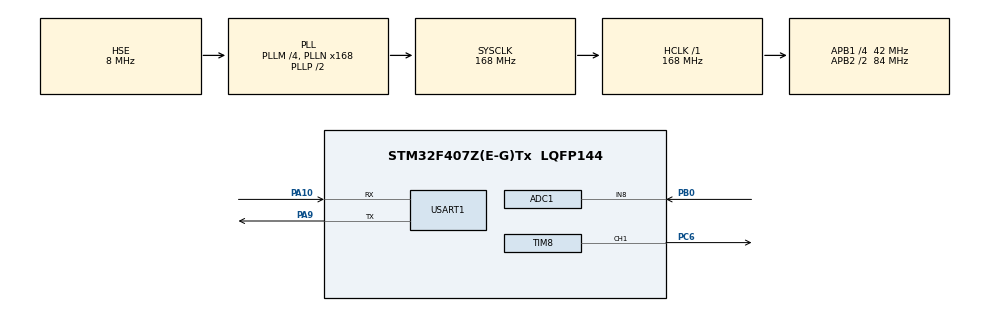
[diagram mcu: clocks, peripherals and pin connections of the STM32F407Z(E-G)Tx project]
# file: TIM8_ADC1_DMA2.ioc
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ADC1.Channel-0\#ChannelRegularConversion=ADC_CHANNEL_8
ADC1.DMAContinuousRequests=ENABLE
ADC1.ExternalTrigConv=ADC_EXTERNALTRIGCONV_T8_CC1
ADC1.NbrOfConversionFlag=1
ADC1.Rank-0\#ChannelRegularConversion=1
ADC1.SamplingTime-0\#ChannelRegularConversion=ADC_SAMPLETIME_15CYCLES
ADC1.master=1
Dma.ADC1.0.Direction=DMA_PERIPH_TO_MEMORY
Dma.ADC1.0.FIFOMode=DMA_FIFOMODE_DISABLE
Dma.ADC1.0.Instance=DMA2_Stream0
Dma.ADC1.0.MemDataAlignment=DMA_MDATAALIGN_HALFWORD
Dma.ADC1.0.MemInc=DMA_MINC_ENABLE
Dma.ADC1.0.Mode=DMA_NORMAL
Dma.ADC1.0.PeriphDataAlignment=DMA_PDATAALIGN_HALFWORD
Dma.ADC1.0.PeriphInc=DMA_PINC_DISABLE
Dma.ADC1.0.Priority=DMA_PRIORITY_MEDIUM
Dma.Request0=ADC1
Mcu.Family=STM32F4
Mcu.Name=STM32F407Z(E-G)Tx
Mcu.Package=LQFP144
NVIC.DMA2_Stream0_IRQn=true\:0\:0\:false\:false\:true\:false\:true\:true
NVIC.PriorityGroup=NVIC_PRIORITYGROUP_4
PA10.Mode=Asynchronous
PA10.Signal=USART1_RX
PA13.Mode=Serial_Wire
PA13.Signal=SYS_JTMS-SWDIO
PA14.Mode=Serial_Wire
PA14.Signal=SYS_JTCK-SWCLK
PA9.Mode=Asynchronous
PA9.Signal=USART1_TX
PB0.Signal=ADCx_IN8
PC14-OSC32_IN.Mode=LSE-External-Oscillator
PC14-OSC32_IN.Signal=RCC_OSC32_IN
PC15-OSC32_OUT.Mode=LSE-External-Oscillator
PC15-OSC32_OUT.Signal=RCC_OSC32_OUT
PC6.Signal=S_TIM8_CH1
PH0-OSC_IN.Mode=HSE-External-Oscillator
PH0-OSC_IN.Signal=RCC_OSC_IN
PH1-OSC_OUT.Mode=HSE-External-Oscillator
PH1-OSC_OUT.Signal=RCC_OSC_OUT
ProjectManager.HeapSize=0x200
ProjectManager.StackSize=0x400
ProjectManager.TargetToolchain=MDK-ARM V5.32
RCC.48MHZClocksFreq_Value=84000000
RCC.AHBFreq_Value=168000000
RCC.APB1CLKDivider=RCC_HCLK_DIV4
RCC.APB1Freq_Value=42000000
RCC.APB1TimFreq_Value=84000000
RCC.APB2CLKDivider=RCC_HCLK_DIV2
RCC.APB2Freq_Value=84000000
RCC.APB2TimFreq_Value=168000000
RCC.CortexFreq_Value=168000000
RCC.HCLKFreq_Value=168000000
RCC.HSE_VALUE=8000000
RCC.HSI_VALUE=16000000
RCC.PLLM=4
RCC.PLLN=168
RCC.PLLSourceVirtual=RCC_PLLSOURCE_HSE
RCC.SYSCLKFreq_VALUE=168000000
RCC.SYSCLKSource=RCC_SYSCLKSOURCE_PLLCLK
RCC.VCOOutputFreq_Value=336000000
SH.ADCx_IN8.0=ADC1_IN8,IN8
SH.S_TIM8_CH1.0=TIM8_CH1,PWM Generation1 CH1
TIM8.Channel-PWM\ Generation1\ CH1=TIM_CHANNEL_1
TIM8.OCPolarity_1=TIM_OCPOLARITY_LOW
TIM8.Period=7999
TIM8.Prescaler=41999
TIM8.Pulse-PWM\ Generation1\ CH1=2999
TIM8.TIM_MasterOutputTrigger=TIM_TRGO_UPDATE
TIM8.TIM_MasterSlaveMode=TIM_MASTERSLAVEMODE_ENABLE
USART1.VirtualMode=VM_ASYNC
VP_TIM8_VS_ClockSourceINT.Mode=Internal
board=custom

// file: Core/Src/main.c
/* USER CODE BEGIN Header */
/**
  ******************************************************************************
  * @file           : main.c
  * @brief          : Main program body
  ******************************************************************************
  * @attention
  *
  * Copyright (c) 2025 STMicroelectronics.
  * All rights reserved.
  *
  * This software is licensed under terms that can be found in the LICENSE file
  * in the root directory of this software component.
  * If no LICENSE file comes with this software, it is provided AS-IS.
  *
  ******************************************************************************
  */
/* USER CODE END Header */
#include "main.h"
#include "adc.h"
#include "dma.h"
#include "tim.h"
#include "usart.h"
#include "gpio.h"
#include "stdio.h"

/* USER CODE BEGIN PD */
#define  ADC_DMA_BUF_SIZE    256         /* ADC DMA采集 BUF大小, 应等于ADC通道数的整数倍 */
#define FRAME_HEADER        0xAA        /* 帧头 */
#define FRAME_TAIL         0xBB        /* 帧尾 */
/* USER CODE END PD */

/* USER CODE BEGIN PV */
uint32_t g_adc_dma_buf[ADC_DMA_BUF_SIZE];   /* ADC DMA BUF 地址 */
volatile uint8_t g_adc_dma_sta;               /* DMA传输状态标志, 0,未完成; 1, 已完成 */

uint8_t txBuf[ADC_DMA_BUF_SIZE * 2 + 2];    /* UART发送缓冲区 */
/* USER CODE END PV */

void SystemClock_Config(void);

int main(void)
{
  /* USER CODE BEGIN 1 */
//  float f_adc;
	float ff_adc;
	float f_adc;
	uint32_t usart1_test = 6;
  /* USER CODE END 1 */

  HAL_Init();
  /* Configure the system clock */
  SystemClock_Config();
  /* Initialize all configured peripherals */
  MX_GPIO_Init();
  MX_DMA_Init();
  MX_ADC1_Init();
  MX_TIM8_Init();
  MX_USART1_UART_Init();
	/* 级联timer输出时序 */
  TIM9_Config();
  TIM1_Config();
  TIM2_Config();
  TIM3_Config();
  TIM4_Config();
  TIM5_Config();
  /* USER CODE BEGIN 2 */
	if(HAL_OK != HAL_ADC_Start(&hadc1))
		Error_Handler();
	if(HAL_OK != HAL_ADC_Start_DMA(&hadc1, (uint32_t*)g_adc_dma_buf, ADC_DMA_BUF_SIZE))
		{
			Error_Handler();
		}
  /* USER CODE END 2 */

  /* Infinite loop */
  while (1)
  {
//		printf("Flag = %d\r\n", g_adc_dma_sta);
		if(g_adc_dma_sta == 1)
    {
			printf("Flag = %d\r\n", g_adc_dma_sta);
			printf("TEST CHAR \r\n");
      for(uint16_t i = 0; i < ADC_DMA_BUF_SIZE; i++)
      {
				f_adc = (float)(g_adc_dma_buf[i] * 3.3f / 4095.0f);
				sendData(f_adc, 4);
			}
      g_adc_dma_sta = 0;
    }
		/* 重新启动ADC采样 */
//		HAL_ADC_Start(&hadc1);
		HAL_ADC_Start_DMA(&hadc1, (uint32_t*)g_adc_dma_buf, ADC_DMA_BUF_SIZE);

  }

}

void SystemClock_Config(void)
{
  RCC_OscInitTypeDef RCC_OscInitStruct = {0};
  RCC_ClkInitTypeDef RCC_ClkInitStruct = {0};

  /** Configure the main internal regulator output voltage
  */
  __HAL_RCC_PWR_CLK_ENABLE();
  __HAL_PWR_VOLTAGESCALING_CONFIG(PWR_REGULATOR_VOLTAGE_SCALE1);

  /** Initializes the RCC Oscillators according to the specified parameters
  * in the RCC_OscInitTypeDef structure.
  */
  RCC_OscInitStruct.OscillatorType = RCC_OSCILLATORTYPE_HSE;
  RCC_OscInitStruct.HSEState = RCC_HSE_ON;
  RCC_OscInitStruct.PLL.PLLState = RCC_PLL_ON;
  RCC_OscInitStruct.PLL.PLLSource = RCC_PLLSOURCE_HSE;
  RCC_OscInitStruct.PLL.PLLM = 4;
  RCC_OscInitStruct.PLL.PLLN = 168;
  RCC_OscInitStruct.PLL.PLLP = RCC_PLLP_DIV2;
  RCC_OscInitStruct.PLL.PLLQ = 4;
  if (HAL_RCC_OscConfig(&RCC_OscInitStruct) != HAL_OK)
  {
    Error_Handler();
  }

  /** Initializes the CPU, AHB and APB buses clocks
  */
  RCC_ClkInitStruct.ClockType = RCC_CLOCKTYPE_HCLK|RCC_CLOCKTYPE_SYSCLK
                              |RCC_CLOCKTYPE_PCLK1|RCC_CLOCKTYPE_PCLK2;
  RCC_ClkInitStruct.SYSCLKSource = RCC_SYSCLKSOURCE_PLLCLK;
  RCC_ClkInitStruct.AHBCLKDivider = RCC_SYSCLK_DIV1;
  RCC_ClkInitStruct.APB1CLKDivider = RCC_HCLK_DIV4;
  RCC_ClkInitStruct.APB2CLKDivider = RCC_HCLK_DIV2;

  if (HAL_RCC_ClockConfig(&RCC_ClkInitStruct, FLASH_LATENCY_5) != HAL_OK)
  {
    Error_Handler();
  }
}

void Error_Handler(void)
{
  __disable_irq();
  while (1)
  {
  }
}
